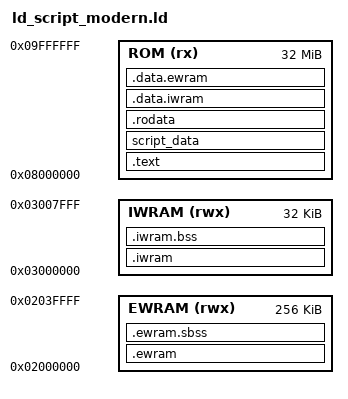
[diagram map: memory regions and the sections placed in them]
ENTRY(Start)

gNumMusicPlayers = 4;
gMaxLines = 0;
gInitialMainCB2 = CB2_InitCopyrightScreenAfterBootup;

MEMORY
{
    EWRAM (rwx) : ORIGIN = 0x2000000, LENGTH = 256K
    IWRAM (rwx) : ORIGIN = 0x3000000, LENGTH = 32K
    ROM    (rx) : ORIGIN = 0x8000000, LENGTH = 32M
}

/* IntrMain runs interrupt handlers on the foreground system stack, so leave
 * room for both SMOL's temporary code buffers and VBlank audio processing.
 * crt0.s uses this same top address when initializing the system SP. */
__system_stack_top = ORIGIN(IWRAM) + 0x8000 - 0x1C0;
__system_stack_size = 0x1000;
__system_stack_bottom = __system_stack_top - __system_stack_size;

SECTIONS {


    .ewram ORIGIN(EWRAM) : AT (__ewram_lma)
    ALIGN(4)
    {
        __ewram_start = .;
        *(.ewram*)
        . = ALIGN(4);
        __ewram_end = .;
    } > EWRAM

    .ewram.sbss (NOLOAD) :
    ALIGN(4)
    {
        *.o(.sbss);
        /* Keep runtime callbacks beyond the legacy multiboot staging area. */
        *(.sbss.main);
    } > EWRAM

    .iwram ORIGIN(IWRAM) : AT (__iwram_lma)
    ALIGN(4)
    {
        __iwram_start = .;
        *(.iwram*);
        . = ALIGN(4);
        __iwram_end = .;
    } > IWRAM

    .iwram.bss (NOLOAD) :
    ALIGN(4)
    {
        *.o(.bss*);
        *.o(common_data);
        src/*.o(COMMON);
        *libc.a:*.o(COMMON);
        *libnosys.a:*.o(COMMON);
        . = ALIGN(4);
        __iwram_data_end = .;
    } > IWRAM

    ASSERT(__iwram_data_end <= __system_stack_bottom,
           "IWRAM data overlaps the reserved 4 KiB system stack")

    /* BEGIN ROM DATA */

    .text ORIGIN(ROM) :
    ALIGN(4)
    {
        src/rom_header.o(.text*);
        KEEP(*.o(.text.header_gf));
        KEEP(*.o(.text.header_rhh));
        src/crt0.o(.text);
        *libagbsyscall.a:*.o(.text*);
        *libgcc.a:*.o(.text*);
        *libc.a:*.o(.text*);
        *libnosys.a:*.o(.text*);
        asm/*.o(.text*);
        KEEP(*.o(.text.consts));
        *.o(.text*);
        *.o(.eh_frame);
    } > ROM =0

    script_data :
    ALIGN(4)
    {
		data/*.o(script_data);
    } > ROM =0

    .rodata :
    ALIGN(4)
    {
        *.o(.rodata*);
        *libgcc.a:*.o(.rodata*);
        *libc.a:*.o(.rodata*);
        *libc.a:*.o(.data*);
        sound/songs/*.o(.rodata);
    } > ROM =0

    .data.iwram :
    ALIGN(4)
    {
        __iwram_lma = .;
        . = . + (__iwram_end - __iwram_start);
    } > ROM = 0

    .data.ewram :
    ALIGN(4)
    {
        __ewram_lma = .;
        . = . + (__ewram_end - __ewram_start);
    } > ROM = 0

    __rom_end = .;

    /* DWARF debug sections.
       Symbols in the DWARF debugging sections are relative to the beginning
       of the section so we begin them at 0.  */

    /* DWARF 1 */
    .debug          0 : { *(.debug) }
    .line           0 : { *(.line) }

    /* GNU DWARF 1 extensions */
    .debug_srcinfo  0 : { *(.debug_srcinfo) }
    .debug_sfnames  0 : { *(.debug_sfnames) }

    /* DWARF 1.1 and DWARF 2 */
    .debug_aranges  0 : { *(.debug_aranges) }
    .debug_pubnames 0 : { *(.debug_pubnames) }

    /* DWARF 2 */
    .debug_info     0 : { *(.debug_info .gnu.linkonce.wi.*) }
    .debug_abbrev   0 : { *(.debug_abbrev) }
    .debug_line     0 : { *(.debug_line) }
    .debug_frame    0 : { *(.debug_frame) }
    .debug_str      0 : { *(.debug_str) }
    .debug_loc      0 : { *(.debug_loc) }
    .debug_macinfo  0 : { *(.debug_macinfo) }

    /* Discard everything not specifically mentioned above. */
    /DISCARD/ :
    {
        *(*);
    }
}
